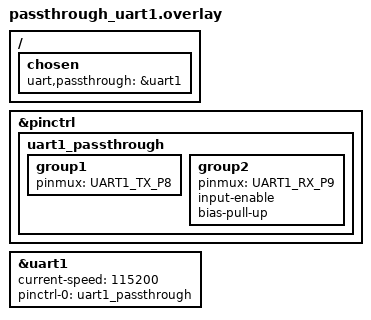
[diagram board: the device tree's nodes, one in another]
/* SPDX-License-Identifier: Apache-2.0 OR MIT */
/*
 * samples/drivers/uart/passthrough copies the console to the
 * uart,passthrough UART and back: uart1 on the straight-through pins, DUT
 * TX GP8 and RX GP9, which the harness joins (a jumper), so what is typed
 * comes back. RX is pulled up so the line idles high before the harness
 * attaches.
 */
/ {
	chosen {
		uart,passthrough = &uart1;
	};
};

&pinctrl {
	uart1_passthrough: uart1_passthrough {
		group1 {
			pinmux = <UART1_TX_P8>;
		};
		group2 {
			pinmux = <UART1_RX_P9>;
			input-enable;
			bias-pull-up;
		};
	};
};

&uart1 {
	status = "okay";
	current-speed = <115200>;
	pinctrl-0 = <&uart1_passthrough>;
	pinctrl-names = "default";
};
